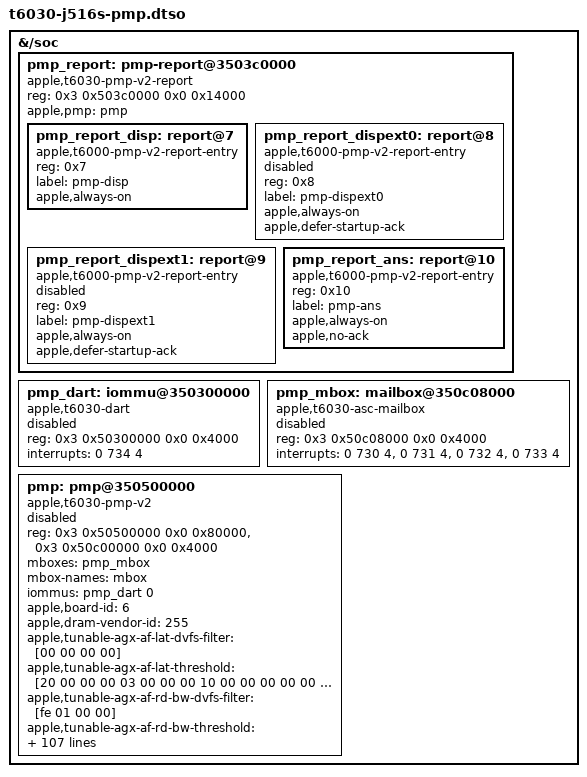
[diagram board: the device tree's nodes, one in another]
// SPDX-License-Identifier: GPL-2.0+ OR MIT
/*
 * J516S (T6030) power management processor, added by the T6030 display
 * gate when it enables the internal display.
 *
 * The PMP, its DART and its mailbox stay disabled here. The PMP report
 * driver sets the display and storage requests in the PTD while the PMP is
 * halted, and enables these nodes, which starts the PMP, only when the
 * display driver first asks for it. The PMP then keeps both powered from
 * the moment it starts.
 * The gate adds the interrupt parent of the DART and the mailbox, which
 * lives in the base tree, and points the DCP at the display report.
 *
 * Addresses, interrupts, the board and DRAM vendor ids and every
 * apple,tunable-* value are those of the J516S ADT pmp, iop-pmp-nub and
 * dart-pmp nodes. apple,tunable-uuid names the firmware image iBoot loads
 * into the PMP SRAM; the report driver refuses to start any other image.
 */

/dts-v1/;
/plugin/;

/ {
	fragment@0 {
		target-path = "/soc";

		__overlay__ {
			#address-cells = <2>;
			#size-cells = <2>;

			pmp_report: pmp-report@3503c0000 {
				compatible = "apple,t6030-pmp-v2-report";
				/* PTD read aperture and update page */
				reg = <0x3 0x503c0000 0x0 0x14000>;
				#address-cells = <1>;
				#size-cells = <0>;
				apple,pmp = <&pmp>;

				/*
				 * The gate points the DCP at this entry (apple,pmp-report)
				 * through the phandle; the overlay itself does not refer to it.
				 */
				pmp_report_disp: report@7 {
					compatible = "apple,t6000-pmp-v2-report-entry";
					reg = <0x7>;
					label = "pmp-disp";
					#power-domain-cells = <0>;
					apple,always-on;
					phandle = <0x100>;
				};

				/* Enabled only by the explicit dcpext gate, before PMP starts. */
				pmp_report_dispext0: report@8 {
					compatible = "apple,t6000-pmp-v2-report-entry";
					reg = <0x8>;
					label = "pmp-dispext0";
					#power-domain-cells = <0>;
					apple,always-on;
					/* Missing external ACK must not block the internal panel. */
					apple,defer-startup-ack;
					phandle = <0x101>;
					status = "disabled";
				};

				/*
				 * The second external display processor. Disabled: no boot
				 * loader hands that processor over yet, so nothing enables it.
				 */
				pmp_report_dispext1: report@9 {
					compatible = "apple,t6000-pmp-v2-report-entry";
					reg = <0x9>;
					label = "pmp-dispext1";
					#power-domain-cells = <0>;
					apple,always-on;
					/* Missing external ACK must not block the internal panel. */
					apple,defer-startup-ack;
					phandle = <0x102>;
					status = "disabled";
				};

				pmp_report_ans: report@10 {
					compatible = "apple,t6000-pmp-v2-report-entry";
					reg = <0x10>;
					label = "pmp-ans";
					#power-domain-cells = <0>;
					apple,always-on;
					/* The PMP does not acknowledge storage requests. */
					apple,no-ack;
				};
			};

			pmp_dart: iommu@350300000 {
				compatible = "apple,t6030-dart", "apple,t8110-dart";
				reg = <0x3 0x50300000 0x0 0x4000>;
				#iommu-cells = <1>;
				interrupts = <0 734 4>;
				status = "disabled";
			};

			pmp_mbox: mailbox@350c08000 {
				compatible = "apple,t6030-asc-mailbox", "apple,asc-mailbox-v4";
				reg = <0x3 0x50c08000 0x0 0x4000>;
				interrupts = <0 730 4>, <0 731 4>, <0 732 4>, <0 733 4>;
				interrupt-names = "send-empty", "send-not-empty",
						  "recv-empty", "recv-not-empty";
				#mbox-cells = <0>;
				status = "disabled";
			};

			pmp: pmp@350500000 {
				compatible = "apple,t6030-pmp-v2", "apple,t6000-pmp-v2";
				reg = <0x3 0x50500000 0x0 0x80000>,
				      <0x3 0x50c00000 0x0 0x4000>;
				reg-names = "pmp", "asc";
				mboxes = <&pmp_mbox>;
				mbox-names = "mbox";
				iommus = <&pmp_dart 0>;
				status = "disabled";
				apple,board-id = <6>;
				apple,dram-vendor-id = <255>;
				apple,tunable-agx-af-lat-dvfs-filter = [00 00 00 00];
				apple,tunable-agx-af-lat-threshold = [20 00 00 00 03 00 00 00 10 00 00 00 00 00 00 00 90 01 00 00 00 00 00 00 c8 00 00 00 03 00 00 00 20 00 00 00 03 00 00 00 10 00 00 00 00 00 00 00 90 01 00 00 00 00 00 00 c8 00 00 00 03 00 00 00 20 00 00 00 03 00 00 00 10 00 00 00 00 00 00 00 90 01 00 00 00 00 00 00 c8 00 00 00 03 00 00 00 20 00 00 00 03 00 00 00 10 00 00 00 00 00 00 00 90 01 00 00 00 00 00 00 c8 00 00 00 03 00 00 00 20 00 00 00 03 00 00 00 10 00 00 00 00 00 00 00 90 01 00 00 00 00 00 00 c8 00 00 00 03 00 00 00 20 00 00 00 03 00 00 00 10 00 00 00 00 00 00 00 90 01 00 00 00 00 00 00 c8 00 00 00 03 00 00 00 20 00 00 00 03 00 00 00 10 00 00 00 00 00 00 00 90 01 00 00 00 00 00 00 c8 00 00 00 03 00 00 00 20 00 00 00 03 00 00 00 10 00 00 00 00 00 00 00 90 01 00 00 00 00 00 00 c8 00 00 00 03 00 00 00 20 00 00 00 03 00 00 00 10 00 00 00 00 00 00 00 90 01 00 00 00 00 00 00 c8 00 00 00 03 00 00 00 20 00 00 00 03 00 00 00 10 00 00 00 00 00 00 00 90 01 00 00 00 00 00 00 c8 00 00 00 03 00 00 00 20 00 00 00 03 00 00 00 10 00 00 00 00 00 00 00 90 01 00 00 00 00 00 00 c8 00 00 00 03 00 00 00 20 00 00 00 03 00 00 00 10 00 00 00 00 00 00 00 90 01 00 00 00 00 00 00 c8 00 00 00 03 00 00 00 20 00 00 00 03 00 00 00 10 00 00 00 00 00 00 00 90 01 00 00 00 00 00 00 c8 00 00 00 03 00 00 00 20 00 00 00 03 00 00 00 10 00 00 00 00 00 00 00 90 01 00 00 00 00 00 00 c8 00 00 00 03 00 00 00 20 00 00 00 03 00 00 00 10 00 00 00 00 00 00 00 90 01 00 00 00 00 00 00 c8 00 00 00 03 00 00 00 20 00 00 00 03 00 00 00 10 00 00 00 00 00 00 00 90 01 00 00 00 00 00 00 c8 00 00 00 03 00 00 00 20 00 00 00 03 00 00 00 10 00 00 00 00 00 00 00 90 01 00 00 00 00 00 00 c8 00 00 00 03 00 00 00 20 00 00 00 03 00 00 00 10 00 00 00 00 00 00 00 90 01 00 00 00 00 00 00 c8 00 00 00 03 00 00 00 20 00 00 00 03 00 00 00 10 00 00 00 00 00 00 00 90 01 00 00 00 00 00 00 c8 00 00 00 03 00 00 00 20 00 00 00 03 00 00 00 10 00 00 00 00 00 00 00 90 01 00 00 00 00 00 00 c8 00 00 00 03 00 00 00 20 00 00 00 03 00 00 00 10 00 00 00 00 00 00 00 90 01 00 00 00 00 00 00 c8 00 00 00 03 00 00 00 20 00 00 00 03 00 00 00 10 00 00 00 00 00 00 00 90 01 00 00 00 00 00 00 c8 00 00 00 03 00 00 00 20 00 00 00 03 00 00 00 10 00 00 00 00 00 00 00 90 01 00 00 00 00 00 00 c8 00 00 00 03 00 00 00 20 00 00 00 03 00 00 00 10 00 00 00 00 00 00 00 90 01 00 00 00 00 00 00 c8 00 00 00 03 00 00 00 20 00 00 00 03 00 00 00 10 00 00 00 00 00 00 00 90 01 00 00 00 00 00 00 c8 00 00 00 03 00 00 00 20 00 00 00 03 00 00 00 10 00 00 00 00 00 00 00 90 01 00 00 00 00 00 00 c8 00 00 00 03 00 00 00 20 00 00 00 03 00 00 00 10 00 00 00 00 00 00 00 90 01 00 00 00 00 00 00 c8 00 00 00 03 00 00 00];
				apple,tunable-agx-af-rd-bw-dvfs-filter = [fe 01 00 00];
				apple,tunable-agx-af-rd-bw-threshold = [00 00 00 00 00 00 00 00 00 00 00 00 00 00 00 00 00 00 00 00 00 00 00 00 00 00 00 00 06 00 00 00 00 00 00 00 00 00 00 00 00 00 00 00 06 00 00 00 00 00 37 00 00 00 00 00 00 00 00 00 00 00 00 00 00 00 57 00 00 00 00 00 00 00 36 00 06 00 00 00 00 00 00 00 00 00 00 00 00 00 56 00 06 00 00 00 00 00 1e 00 00 00 00 00 00 00 00 00 00 00 00 00 00 00 57 00 00 00 00 00 00 00 1d 00 06 00 00 00 00 00 00 00 00 00 00 00 00 00 56 00 06 00 00 00 00 00 16 00 00 00 00 00 00 00 00 00 00 00 00 00 00 00 57 00 00 00 00 00 00 00 15 00 06 00 00 00 00 00 00 00 00 00 00 00 00 00 56 00 06 00 00 00 00 00 0a 00 00 00 00 00 00 00 00 00 00 00 00 00 00 00 57 00 00 00 00 00 00 00 09 00 06 00 00 00 00 00 00 00 00 00 00 00 00 00 56 00 06 00 00 00 00 00 01 00 00 00 00 00 00 00 00 00 00 00 00 00 00 00 57 00 00 00 00 00 00 00 00 00 06 00 00 00 00 00 00 00 00 00 00 00 00 00 56 00 06 00 00 00 00 00 01 00 00 00 00 00 00 00 00 00 00 00 00 00 00 00 14 00 00 00 00 00 00 00 00 00 06 00 00 00 00 00 00 00 00 00 00 00 00 00 13 00 06 00 00 00 00 00 01 00 00 00 00 00 00 00 00 00 00 00 00 00 00 00 01 00 00 00 00 00 00 00 00 00 06 00 00 00 00 00 00 00 00 00 00 00 00 00 00 00 06 00 00 00 00 00 01 00 00 00 00 00 00 00 00 00 00 00 00 00 00 00 01 00 00 00 00 00 00 00 00 00 06 00 00 00 00 00 00 00 00 00 00 00 00 00 00 00 06 00 00 00];
				apple,tunable-agx-af-wr-bw-dvfs-filter = [fe 01 00 00];
				apple,tunable-agx-af-wr-bw-threshold = [00 00 00 00 00 00 00 00 00 00 00 00 00 00 00 00 00 00 00 00 00 00 00 00 00 00 00 00 06 00 00 00 00 00 00 00 00 00 00 00 00 00 00 00 06 00 00 00 00 00 37 00 00 00 00 00 00 00 00 00 00 00 00 00 00 00 57 00 00 00 00 00 00 00 36 00 06 00 00 00 00 00 00 00 00 00 00 00 00 00 56 00 06 00 00 00 00 00 1e 00 00 00 00 00 00 00 00 00 00 00 00 00 00 00 57 00 00 00 00 00 00 00 1d 00 06 00 00 00 00 00 00 00 00 00 00 00 00 00 56 00 06 00 00 00 00 00 16 00 00 00 00 00 00 00 00 00 00 00 00 00 00 00 57 00 00 00 00 00 00 00 15 00 06 00 00 00 00 00 00 00 00 00 00 00 00 00 56 00 06 00 00 00 00 00 0a 00 00 00 00 00 00 00 00 00 00 00 00 00 00 00 57 00 00 00 00 00 00 00 09 00 06 00 00 00 00 00 00 00 00 00 00 00 00 00 56 00 06 00 00 00 00 00 01 00 00 00 00 00 00 00 00 00 00 00 00 00 00 00 57 00 00 00 00 00 00 00 00 00 06 00 00 00 00 00 00 00 00 00 00 00 00 00 56 00 06 00 00 00 00 00 01 00 00 00 00 00 00 00 00 00 00 00 00 00 00 00 14 00 00 00 00 00 00 00 00 00 06 00 00 00 00 00 00 00 00 00 00 00 00 00 13 00 06 00 00 00 00 00 01 00 00 00 00 00 00 00 00 00 00 00 00 00 00 00 01 00 00 00 00 00 00 00 00 00 06 00 00 00 00 00 00 00 00 00 00 00 00 00 00 00 06 00 00 00 00 00 01 00 00 00 00 00 00 00 00 00 00 00 00 00 00 00 01 00 00 00 00 00 00 00 00 00 06 00 00 00 00 00 00 00 00 00 00 00 00 00 00 00 06 00 00 00];
				apple,tunable-agx-dcs-bw-dvfs-filter = [fe 01 00 00];
				apple,tunable-agx-dcs-bw-threshold = [00 00 00 00 00 00 00 00 00 00 00 00 00 00 00 00 00 00 00 00 00 00 00 00 00 00 00 00 06 00 00 00 00 00 00 00 00 00 00 00 00 00 00 00 06 00 00 00 00 00 00 00 00 00 00 00 00 00 00 00 06 00 00 00 00 00 00 00 00 00 00 00 00 00 00 00 06 00 00 00 00 00 10 00 00 00 00 00 00 00 00 00 00 00 00 00 00 00 3c 00 00 00 00 00 00 00 0f 00 06 00 00 00 00 00 4c 00 00 00 00 00 00 00 3b 00 06 00 00 00 00 00 66 00 00 00 00 00 00 00 4b 00 06 00 00 00 00 00 00 00 00 00 00 00 00 00 65 00 06 00 00 00 00 00 0a 00 00 00 00 00 00 00 00 00 00 00 00 00 00 00 3c 00 00 00 00 00 00 00 09 00 06 00 00 00 00 00 4c 00 00 00 00 00 00 00 3b 00 06 00 00 00 00 00 66 00 00 00 00 00 00 00 4b 00 06 00 00 00 00 00 00 00 00 00 00 00 00 00 65 00 06 00 00 00 00 00 04 00 00 00 00 00 00 00 00 00 00 00 00 00 00 00 2c 00 00 00 00 00 00 00 03 00 06 00 00 00 00 00 4c 00 00 00 00 00 00 00 2b 00 06 00 00 00 00 00 57 00 00 00 00 00 00 00 4b 00 06 00 00 00 00 00 00 00 00 00 00 00 00 00 56 00 06 00 00 00 00 00 01 00 00 00 00 00 00 00 00 00 00 00 00 00 00 00 1a 00 00 00 00 00 00 00 00 00 06 00 00 00 00 00 26 00 00 00 00 00 00 00 19 00 06 00 00 00 00 00 57 00 00 00 00 00 00 00 25 00 06 00 00 00 00 00 00 00 00 00 00 00 00 00 56 00 06 00 00 00 00 00 01 00 00 00 00 00 00 00 00 00 00 00 00 00 00 00 01 00 00 00 00 00 00 00 00 00 06 00 00 00 00 00 0c 00 00 00 00 00 00 00 00 00 06 00 00 00 00 00 33 00 00 00 00 00 00 00 0b 00 06 00 00 00 00 00 00 00 00 00 00 00 00 00 32 00 06 00 00 00 00 00 01 00 00 00 00 00 00 00 00 00 00 00 00 00 00 00 01 00 00 00 00 00 00 00 00 00 06 00 00 00 00 00 01 00 00 00 00 00 00 00 00 00 06 00 00 00 00 00 20 00 00 00 00 00 00 00 00 00 06 00 00 00 00 00 00 00 00 00 00 00 00 00 1f 00 06 00 00 00 00 00 01 00 00 00 00 00 00 00 00 00 00 00 00 00 00 00 01 00 00 00 00 00 00 00 00 00 06 00 00 00 00 00 01 00 00 00 00 00 00 00 00 00 06 00 00 00 00 00 01 00 00 00 00 00 00 00 00 00 06 00 00 00 00 00 00 00 00 00 00 00 00 00 00 00 06 00 00 00 00 00 01 00 00 00 00 00 00 00 00 00 00 00 00 00 00 00 01 00 00 00 00 00 00 00 00 00 06 00 00 00 00 00 01 00 00 00 00 00 00 00 00 00 06 00 00 00 00 00 01 00 00 00 00 00 00 00 00 00 06 00 00 00 00 00 00 00 00 00 00 00 00 00 00 00 06 00 00 00];
				apple,tunable-agx-dcs-lat-dvfs-filter = [00 00 00 00];
				apple,tunable-agx-dcs-lat-threshold = [20 00 00 00 03 00 00 00 10 00 00 00 00 00 00 00 90 01 00 00 00 00 00 00 c8 00 00 00 03 00 00 00 20 00 00 00 03 00 00 00 10 00 00 00 00 00 00 00 90 01 00 00 00 00 00 00 c8 00 00 00 03 00 00 00 20 00 00 00 03 00 00 00 10 00 00 00 00 00 00 00 90 01 00 00 00 00 00 00 c8 00 00 00 03 00 00 00 20 00 00 00 03 00 00 00 10 00 00 00 00 00 00 00 90 01 00 00 00 00 00 00 c8 00 00 00 03 00 00 00 20 00 00 00 03 00 00 00 10 00 00 00 00 00 00 00 90 01 00 00 00 00 00 00 c8 00 00 00 03 00 00 00 20 00 00 00 03 00 00 00 10 00 00 00 00 00 00 00 90 01 00 00 00 00 00 00 c8 00 00 00 03 00 00 00 20 00 00 00 03 00 00 00 10 00 00 00 00 00 00 00 90 01 00 00 00 00 00 00 c8 00 00 00 03 00 00 00 20 00 00 00 03 00 00 00 10 00 00 00 00 00 00 00 90 01 00 00 00 00 00 00 c8 00 00 00 03 00 00 00 20 00 00 00 03 00 00 00 10 00 00 00 00 00 00 00 90 01 00 00 00 00 00 00 c8 00 00 00 03 00 00 00 20 00 00 00 03 00 00 00 10 00 00 00 00 00 00 00 90 01 00 00 00 00 00 00 c8 00 00 00 03 00 00 00 20 00 00 00 03 00 00 00 10 00 00 00 00 00 00 00 90 01 00 00 00 00 00 00 c8 00 00 00 03 00 00 00 20 00 00 00 03 00 00 00 10 00 00 00 00 00 00 00 90 01 00 00 00 00 00 00 c8 00 00 00 03 00 00 00 20 00 00 00 03 00 00 00 10 00 00 00 00 00 00 00 90 01 00 00 00 00 00 00 c8 00 00 00 03 00 00 00 20 00 00 00 03 00 00 00 10 00 00 00 00 00 00 00 90 01 00 00 00 00 00 00 c8 00 00 00 03 00 00 00 20 00 00 00 03 00 00 00 10 00 00 00 00 00 00 00 90 01 00 00 00 00 00 00 c8 00 00 00 03 00 00 00 20 00 00 00 03 00 00 00 10 00 00 00 00 00 00 00 90 01 00 00 00 00 00 00 c8 00 00 00 03 00 00 00 20 00 00 00 03 00 00 00 10 00 00 00 00 00 00 00 90 01 00 00 00 00 00 00 c8 00 00 00 03 00 00 00 20 00 00 00 03 00 00 00 10 00 00 00 00 00 00 00 90 01 00 00 00 00 00 00 c8 00 00 00 03 00 00 00 20 00 00 00 03 00 00 00 10 00 00 00 00 00 00 00 90 01 00 00 00 00 00 00 c8 00 00 00 03 00 00 00 20 00 00 00 03 00 00 00 10 00 00 00 00 00 00 00 90 01 00 00 00 00 00 00 c8 00 00 00 03 00 00 00 20 00 00 00 03 00 00 00 10 00 00 00 00 00 00 00 90 01 00 00 00 00 00 00 c8 00 00 00 03 00 00 00 20 00 00 00 03 00 00 00 10 00 00 00 00 00 00 00 90 01 00 00 00 00 00 00 c8 00 00 00 03 00 00 00 20 00 00 00 03 00 00 00 10 00 00 00 00 00 00 00 90 01 00 00 00 00 00 00 c8 00 00 00 03 00 00 00 20 00 00 00 03 00 00 00 10 00 00 00 00 00 00 00 90 01 00 00 00 00 00 00 c8 00 00 00 03 00 00 00 20 00 00 00 03 00 00 00 10 00 00 00 00 00 00 00 90 01 00 00 00 00 00 00 c8 00 00 00 03 00 00 00 20 00 00 00 03 00 00 00 10 00 00 00 00 00 00 00 90 01 00 00 00 00 00 00 c8 00 00 00 03 00 00 00 20 00 00 00 03 00 00 00 10 00 00 00 00 00 00 00 90 01 00 00 00 00 00 00 c8 00 00 00 03 00 00 00 20 00 00 00 03 00 00 00 10 00 00 00 00 00 00 00 90 01 00 00 00 00 00 00 c8 00 00 00 03 00 00 00 20 00 00 00 03 00 00 00 10 00 00 00 00 00 00 00 90 01 00 00 00 00 00 00 c8 00 00 00 03 00 00 00 20 00 00 00 03 00 00 00 10 00 00 00 00 00 00 00 90 01 00 00 00 00 00 00 c8 00 00 00 03 00 00 00 20 00 00 00 03 00 00 00 10 00 00 00 00 00 00 00 90 01 00 00 00 00 00 00 c8 00 00 00 03 00 00 00 20 00 00 00 03 00 00 00 10 00 00 00 00 00 00 00 90 01 00 00 00 00 00 00 c8 00 00 00 03 00 00 00 20 00 00 00 03 00 00 00 10 00 00 00 00 00 00 00 90 01 00 00 00 00 00 00 c8 00 00 00 03 00 00 00 20 00 00 00 03 00 00 00 10 00 00 00 00 00 00 00 90 01 00 00 00 00 00 00 c8 00 00 00 03 00 00 00 20 00 00 00 03 00 00 00 10 00 00 00 00 00 00 00 90 01 00 00 00 00 00 00 c8 00 00 00 03 00 00 00 20 00 00 00 03 00 00 00 10 00 00 00 00 00 00 00 90 01 00 00 00 00 00 00 c8 00 00 00 03 00 00 00 20 00 00 00 03 00 00 00 10 00 00 00 00 00 00 00 90 01 00 00 00 00 00 00 c8 00 00 00 03 00 00 00 20 00 00 00 03 00 00 00 10 00 00 00 00 00 00 00 90 01 00 00 00 00 00 00 c8 00 00 00 03 00 00 00 20 00 00 00 03 00 00 00 10 00 00 00 00 00 00 00 90 01 00 00 00 00 00 00 c8 00 00 00 03 00 00 00 20 00 00 00 03 00 00 00 10 00 00 00 00 00 00 00 90 01 00 00 00 00 00 00 c8 00 00 00 03 00 00 00 20 00 00 00 03 00 00 00 10 00 00 00 00 00 00 00 90 01 00 00 00 00 00 00 c8 00 00 00 03 00 00 00 20 00 00 00 03 00 00 00 10 00 00 00 00 00 00 00 90 01 00 00 00 00 00 00 c8 00 00 00 03 00 00 00 20 00 00 00 03 00 00 00 10 00 00 00 00 00 00 00 90 01 00 00 00 00 00 00 c8 00 00 00 03 00 00 00 20 00 00 00 03 00 00 00 10 00 00 00 00 00 00 00 90 01 00 00 00 00 00 00 c8 00 00 00 03 00 00 00 20 00 00 00 03 00 00 00 10 00 00 00 00 00 00 00 90 01 00 00 00 00 00 00 c8 00 00 00 03 00 00 00];
				apple,tunable-agx-dvfs-state-voltages = [7d 00 00 00 8f 02 00 00 b7 02 00 00 cb 02 00 00 ee 02 00 00 ee 02 00 00 2a 03 00 00 2a 03 00 00 6b 03 00 00 6b 03 00 00 9d 03 00 00 9d 03 00 00 bb 03 00 00 bb 03 00 00 7d 00 00 00 7d 00 00 00];
				apple,tunable-ane-fast-af-bw-dvfs-filter = [e0 ff ff 0f];
				apple,tunable-ane-fast-af-bw-threshold = [00 00 05 00 00 00 00 00 00 00 00 00 00 00 00 00 00 00 0e 00 00 00 00 00 00 00 04 00 06 00 00 00 00 00 00 00 00 00 00 00 00 00 0d 00 06 00 00 00];
				apple,tunable-ane-fast-bw-dvfs-filter = [e0 ff ff 0f];
				apple,tunable-ane-fast-bw-threshold = [00 00 05 00 00 00 00 00 00 00 00 00 00 00 00 00 00 00 0e 00 00 00 00 00 00 00 04 00 06 00 00 00 00 00 00 00 00 00 00 00 00 00 0d 00 06 00 00 00];
				apple,tunable-ane-fast-dcs-bw-dvfs-filter = [00 fe ff 0f];
				apple,tunable-ane-fast-dcs-bw-threshold = [00 00 07 00 00 00 00 00 00 00 00 00 00 00 00 00 00 00 0f 00 00 00 00 00 00 00 06 00 06 00 00 00 00 00 2d 00 00 00 00 00 00 00 0e 00 06 00 00 00 00 00 4b 00 00 00 00 00 00 00 2c 00 06 00 00 00 00 00 00 00 00 00 00 00 00 00 4a 00 06 00 00 00];
				apple,tunable-ane-slow-af-bw-dvfs-filter = [1c 00 00 00];
				apple,tunable-ane-slow-af-bw-threshold = [47 a1 19 00 00 00 00 00 00 00 00 00 00 00 00 00 14 2e 22 00 00 00 00 00 47 a1 18 00 03 00 00 00 00 00 00 00 00 00 00 00 14 2e 21 00 03 00 00 00];
				apple,tunable-ane-slow-bw-dvfs-filter = [1f 00 00 00];
				apple,tunable-ane-slow-bw-threshold = [47 a1 19 00 00 00 00 00 00 00 00 00 00 00 00 00 14 2e 22 00 00 00 00 00 47 a1 18 00 03 00 00 00 00 00 00 00 00 00 00 00 14 2e 21 00 03 00 00 00];
				apple,tunable-ane-slow-dcs-bw-dvfs-filter = [e0 01 00 00];
				apple,tunable-ane-slow-dcs-bw-threshold = [00 00 0f 00 00 00 00 00 00 00 00 00 00 00 00 00 00 00 2a 00 00 00 00 00 00 00 0e 00 06 00 00 00 00 00 52 00 00 00 00 00 00 00 29 00 06 00 00 00 00 00 69 00 00 00 00 00 00 00 51 00 06 00 00 00 00 00 00 00 00 00 00 00 00 00 68 00 06 00 00 00];
				apple,tunable-bwr-catch-up-factor = [00 00 01 00];
				apple,tunable-controller = [01 00 00 00 1f 00 00 00 43 00 00 00 44 49 45 2d 54 45 4d 50 00 00 00 00 00 00 00 00 00 00 00 00 00 00 00 00 00 00 00 00 00 00 00 00 02 00 00 00 00 00 00 00 00 00 00 00 44 43 53 2d 42 57 00 00 00 00 00 00 00 00 00 00 00 00 00 00 00 00 00 00 00 00 00 00 00 00 00 00 03 00 00 00 00 00 00 00 00 00 00 00 41 47 58 2d 41 46 2d 52 44 2d 42 57 00 00 00 00 00 00 00 00 00 00 00 00 00 00 00 00 00 00 00 00 05 00 00 00 00 00 00 00 00 00 00 00 41 47 58 2d 41 46 2d 57 52 2d 42 57 00 00 00 00 00 00 00 00 00 00 00 00 00 00 00 00 00 00 00 00 07 00 00 00 00 00 00 00 00 00 00 00 41 47 58 2d 44 43 53 2d 42 57 00 00 00 00 00 00 00 00 00 00 00 00 00 00 00 00 00 00 00 00 00 00 09 00 00 00 00 00 00 00 00 00 00 00 44 43 53 2d 42 57 52 00 00 00 00 00 00 00 00 00 00 00 00 00 00 00 00 00 00 00 00 00 00 00 00 00 0a 00 00 00 00 00 00 00 00 00 00 00 44 43 53 2d 52 44 2d 42 57 52 00 00 00 00 00 00 00 00 00 00 00 00 00 00 00 00 00 00 00 00 00 00 0b 00 00 00 00 00 00 00 00 00 00 00 44 43 53 2d 57 52 2d 42 57 52 00 00 00 00 00 00 00 00 00 00 00 00 00 00 00 00 00 00 00 00 00 00 0c 00 00 00 00 00 00 00 00 00 00 00 53 4f 43 30 2d 52 44 2d 42 57 52 00 00 00 00 00 00 00 00 00 00 00 00 00 00 00 00 00 00 00 00 00 0d 00 00 00 00 00 00 00 00 00 00 00 53 4f 43 30 2d 57 52 2d 42 57 52 00 00 00 00 00 00 00 00 00 00 00 00 00 00 00 00 00 00 00 00 00 0e 00 00 00 00 00 00 00 00 00 00 00 53 4f 43 31 2d 52 44 2d 42 57 52 00 00 00 00 00 00 00 00 00 00 00 00 00 00 00 00 00 00 00 00 00 0f 00 00 00 00 00 00 00 00 00 00 00 53 4f 43 31 2d 57 52 2d 42 57 52 00 00 00 00 00 00 00 00 00 00 00 00 00 00 00 00 00 00 00 00 00 10 00 00 00 00 00 00 00 00 00 00 00 41 4e 45 2d 53 4c 4f 57 2d 44 43 53 2d 42 57 00 00 00 00 00 00 00 00 00 00 00 00 00 00 00 00 00 11 00 00 00 00 00 00 00 00 00 00 00 41 4e 45 2d 46 41 53 54 2d 44 43 53 2d 42 57 00 00 00 00 00 00 00 00 00 00 00 00 00 00 00 00 00 12 00 00 00 00 00 00 00 00 00 00 00 41 4e 45 2d 53 4c 4f 57 2d 41 46 2d 42 57 00 00 00 00 00 00 00 00 00 00 00 00 00 00 00 00 00 00 13 00 00 00 00 00 00 00 00 00 00 00 41 4e 45 2d 46 41 53 54 2d 41 46 2d 42 57 00 00 00 00 00 00 00 00 00 00 00 00 00 00 00 00 00 00 14 00 00 00 00 00 00 00 00 00 00 00 41 4e 45 2d 53 4c 4f 57 2d 42 57 00 00 00 00 00 00 00 00 00 00 00 00 00 00 00 00 00 00 00 00 00 15 00 00 00 00 00 00 00 00 00 00 00 41 4e 45 2d 46 41 53 54 2d 42 57 00 00 00 00 00 00 00 00 00 00 00 00 00 00 00 00 00 00 00 00 00 16 00 00 00 0e 00 00 00 1e 00 00 00 4d 45 4d 2d 43 41 43 48 45 00 00 00 00 00 00 00 00 00 00 00 00 00 00 00 00 00 00 00 00 00 00 00 17 00 00 00 00 00 00 00 00 00 00 00 41 47 58 2d 41 46 2d 4c 41 54 00 00 00 00 00 00 00 00 00 00 00 00 00 00 00 00 00 00 00 00 00 00 18 00 00 00 00 00 00 00 00 00 00 00 41 47 58 2d 44 43 53 2d 4c 41 54 00 00 00 00 00 00 00 00 00 00 00 00 00 00 00 00 00 00 00 00 00 19 00 00 00 00 00 00 00 00 00 00 00 49 4f 41 30 2d 41 46 4e 43 2d 42 57 00 00 00 00 00 00 00 00 00 00 00 00 00 00 00 00 00 00 00 00 1a 00 00 00 00 00 00 00 00 00 00 00 49 4f 41 31 2d 41 46 4e 43 2d 42 57 00 00 00 00 00 00 00 00 00 00 00 00 00 00 00 00 00 00 00 00 1b 00 00 00 00 00 00 00 00 00 00 00 49 4f 41 32 2d 41 46 4e 43 2d 42 57 00 00 00 00 00 00 00 00 00 00 00 00 00 00 00 00 00 00 00 00 1c 00 00 00 00 00 00 00 00 00 00 00 49 4f 41 33 2d 41 46 4e 43 2d 42 57 00 00 00 00 00 00 00 00 00 00 00 00 00 00 00 00 00 00 00 00];
				apple,tunable-dcs-bw-threshold = [7a d4 1d 00 00 00 00 00 00 00 00 00 00 00 00 00 00 c0 3b 00 00 00 00 00 7a d4 1c 00 03 00 00 00 3d 0a 57 00 00 00 00 00 00 c0 3a 00 03 00 00 00 1e 85 6f 00 00 00 00 00 3d 0a 56 00 03 00 00 00 00 00 00 00 00 00 00 00 1e 85 6e 00 03 00 00 00];
				apple,tunable-dcs-bwr-threshold = [00 80 11 00 99 19 23 00 33 33 33 00 99 99 41 00 cc cc 4c 00];
				apple,tunable-dcs-rd-bwr-threshold = [00 80 11 00 99 19 23 00 33 33 33 00 99 99 41 00 cc cc 4c 00];
				apple,tunable-dcs-wr-bwr-threshold = [00 80 0a 00 99 19 15 00 33 b3 1e 00 66 66 27 00 99 19 2e 00];
				apple,tunable-dvfs-disp-min-state = [00 00 00 00];
				apple,tunable-dvfs-domain = [01 00 00 00 05 00 00 00 00 00 00 00 44 43 53 00 00 00 00 00 00 00 00 00 00 00 00 00 02 00 00 00 03 00 00 00 00 00 00 00 53 4f 43 00 00 00 00 00 00 00 00 00 00 00 00 00 03 00 00 00 03 00 00 00 00 00 00 00 44 49 53 50 5f 49 4e 54 00 00 00 00 00 00 00 00 04 00 00 00 03 00 00 00 00 00 00 00 46 41 42 00 00 00 00 00 00 00 00 00 00 00 00 00 05 00 00 00 04 00 00 00 00 00 00 00 44 49 53 50 5f 45 58 54 00 00 00 00 00 00 00 00];
				apple,tunable-fast-die-ctrl-ce-map = [01 00 00 00 00 00 00 00 00 00 00 00 01 00 00 00 00 00 00 00 00 00 00 00 00 00 00 00 45 41 43 43 00 00 00 00 00 00 00 00 00 00 00 00 02 00 00 00 00 00 00 00 01 00 00 00 02 00 00 00 03 00 00 00 00 00 00 00 00 00 00 00 50 41 43 43 5f 41 4e 45 00 00 00 00 00 00 00 00];
				apple,tunable-fast-die-ctrl-loop = [01 00 00 00 00 00 00 00 00 00 00 00 ae 05 00 00 cc cc 07 00 00 00 6e 00 00 00 01 00 00 00 00 00 00 00 01 00 00 00 00 00 00 00 00 00 00 00 01 00 16 00 00 00 02 00 00 00 03 00 00 00 00 00 00 00 00 00 00 00 00 00 00 00 00 00 00 00 00 00 00 00 00 00 00 00 00 00 00 00 00 00 00 00 00 00 00 00 00 00 00 00 00 00 00 00 00 00 00 00 00 00 00 00 00 00 00 00 45 41 43 43 00 00 00 00 00 00 00 00 00 00 00 00 02 00 00 00 00 00 00 00 01 00 00 00 ae 05 00 00 cc cc 07 00 00 00 6e 00 00 00 01 00 00 00 00 00 00 00 01 00 00 00 00 00 00 00 00 00 00 00 01 00 16 00 00 00 04 00 00 00 05 00 00 00 06 00 00 00 00 00 00 00 00 00 00 00 00 00 00 00 00 00 00 00 00 00 00 00 00 00 00 00 00 00 00 00 00 00 00 00 00 00 00 00 00 00 00 00 00 00 00 00 00 00 00 00 00 00 00 00 50 41 43 43 00 00 00 00 00 00 00 00 00 00 00 00 03 00 00 00 00 00 00 00 02 00 00 00 ae 05 00 00 cc cc 07 00 00 00 6e 00 00 00 01 00 00 00 00 00 00 00 01 00 00 00 00 00 00 00 00 00 00 00 01 00 16 00 00 00 01 00 00 00 00 00 00 00 00 00 00 00 00 00 00 00 00 00 00 00 00 00 00 00 00 00 00 00 00 00 00 00 00 00 00 00 00 00 00 00 00 00 00 00 00 00 00 00 00 00 00 00 00 00 00 00 00 00 00 00 00 00 00 00 41 4e 45 30 00 00 00 00 00 00 00 00 00 00 00 00];
				apple,tunable-fast-die-ctrl-ts = [00 00 05 00];
				apple,tunable-fast-die-ctrl-ts-avg-temp = [00 00 64 00];
				apple,tunable-ioa0-afnc-bw-threshold = [cc 0c 1d 00 00 00 00 00 00 00 00 00 00 00 00 00 e1 ba 26 00 00 00 00 00 cc 0c 1c 00 03 00 00 00 00 00 00 00 00 00 00 00 e1 ba 25 00 03 00 00 00];
				apple,tunable-ioa1-afnc-bw-threshold = [cc 0c 1d 00 00 00 00 00 00 00 00 00 00 00 00 00 e1 ba 26 00 00 00 00 00 cc 0c 1c 00 03 00 00 00 00 00 00 00 00 00 00 00 e1 ba 25 00 03 00 00 00];
				apple,tunable-ioa2-afnc-bw-threshold = [cc 0c 1d 00 00 00 00 00 00 00 00 00 00 00 00 00 e1 ba 26 00 00 00 00 00 cc 0c 1c 00 03 00 00 00 00 00 00 00 00 00 00 00 e1 ba 25 00 03 00 00 00];
				apple,tunable-ioa3-afnc-bw-threshold = [cc 0c 1d 00 00 00 00 00 00 00 00 00 00 00 00 00 e1 ba 26 00 00 00 00 00 cc 0c 1c 00 03 00 00 00 00 00 00 00 00 00 00 00 e1 ba 25 00 03 00 00 00];
				apple,tunable-mc_cmd_ack_ptd_count = [01 00 00 00];
				apple,tunable-mc_cmd_ptd_count = [02 00 00 00];
				apple,tunable-mc_quota_req_ptd_count = [08 00 00 00];
				apple,tunable-mc_quota_rsp_ptd_count = [08 00 00 00];
				apple,tunable-mcache-stream = [1e 00 00 00 03 00 00 00 01 00 00 00 0b 00 00 00 0e 00 00 00 0e 00 00 00 02 00 00 00 00 00 00 00 00 00 00 00 04 00 00 00 01 00 00 00 05 00 00 00 01 00 00 00 01 00 00 00 02 00 00 00 14 00 00 00 14 00 00 00 02 00 00 00 00 00 00 00 00 00 00 00 04 00 00 00 01 00 00 00 06 00 00 00 02 00 00 00 01 00 00 00 03 00 00 00 12 00 00 00 12 00 00 00 02 00 00 00 00 00 00 00 00 00 00 00 04 00 00 00 00 00 00 00 0b 00 00 00 05 00 00 00 01 00 00 00 05 00 00 00 21 00 00 00 21 00 00 00 02 00 00 00 00 00 00 00 00 00 00 00 04 00 00 00 01 00 00 00 0e 00 00 00 04 00 00 00 01 00 00 00 10 00 00 00 15 00 00 00 15 00 00 00 02 00 00 00 00 00 00 00 00 00 00 00 04 00 00 00 00 00 00 00 11 00 00 00 04 00 00 00 01 00 00 00 11 00 00 00 16 00 00 00 16 00 00 00 02 00 00 00 00 00 00 00 00 00 00 00 04 00 00 00 01 00 00 00 13 00 00 00 04 00 00 00 01 00 00 00 12 00 00 00 17 00 00 00 17 00 00 00 02 00 00 00 00 00 00 00 00 00 00 00 04 00 00 00 01 00 00 00 24 00 00 00 04 00 00 00 01 00 00 00 12 00 00 00 18 00 00 00 18 00 00 00 02 00 00 00 00 00 00 00 00 00 00 00 04 00 00 00 01 00 00 00 1b 00 00 00 04 00 00 00 01 00 00 00 11 00 00 00 1e 00 00 00 1e 00 00 00 02 00 00 00 00 00 00 00 00 00 00 00 04 00 00 00 01 00 00 00 1c 00 00 00 04 00 00 00 01 00 00 00 12 00 00 00 1f 00 00 00 1f 00 00 00 02 00 00 00 00 00 00 00 00 00 00 00 04 00 00 00 01 00 00 00 10 00 00 00 04 00 00 00 01 00 00 00 18 00 00 00 40 00 00 00 bf 00 00 00 02 00 00 00 00 00 00 00 00 00 00 00 04 00 00 00 01 00 00 00 04 00 00 00 00 00 00 00 01 00 00 00 06 00 00 00 0d 00 00 00 0d 00 00 00 02 00 00 00 00 00 00 00 00 00 00 00 05 00 00 00 01 00 00 00 02 00 00 00 00 00 00 00 01 00 00 00 04 00 00 00 13 00 00 00 13 00 00 00 02 00 00 00 00 00 00 00 00 00 00 00 04 00 00 00 01 00 00 00 01 00 00 00 00 00 00 00 01 00 00 00 0a 00 00 00 0a 00 00 00 0c 00 00 00 02 00 00 00 00 00 00 00 00 00 00 00 04 00 00 00 01 00 00 00 1f 00 00 00 03 00 00 00 02 00 00 00 0b 00 00 00 23 00 00 00 23 00 00 00 03 00 00 00 00 00 00 00 00 00 00 00 04 00 00 00 01 00 00 00 20 00 00 00 03 00 00 00 02 00 00 00 16 00 00 00 24 00 00 00 33 00 00 00 03 00 00 00 00 00 00 00 00 00 00 00 05 00 00 00 01 00 00 00 12 00 00 00 05 00 00 00 02 00 00 00 09 00 00 00 0f 00 00 00 0f 00 00 00 03 00 00 00 00 00 00 00 00 00 00 00 04 00 00 00 01 00 00 00 15 00 00 00 07 00 00 00 02 00 00 00 0f 00 00 00 11 00 00 00 11 00 00 00 03 00 00 00 00 00 00 00 00 00 00 00 04 00 00 00 01 00 00 00 21 00 00 00 0a 00 00 00 02 00 00 00 07 00 00 00 20 00 00 00 20 00 00 00 03 00 00 00 00 00 00 00 00 00 00 00 04 00 00 00 00 00 00 00 1d 00 00 00 09 00 00 00 02 00 00 00 13 00 00 00 34 00 00 00 38 00 00 00 03 00 00 00 00 00 00 00 00 00 00 00 04 00 00 00 01 00 00 00 23 00 00 00 00 00 00 00 03 00 00 00 0c 00 00 00 19 00 00 00 19 00 00 00 01 00 00 00 00 00 00 00 00 00 00 00 04 00 00 00 01 00 00 00 19 00 00 00 08 00 00 00 03 00 00 00 01 00 00 00 03 00 00 00 03 00 00 00 01 00 00 00 00 00 00 00 00 00 00 00 04 00 00 00 01 00 00 00 1a 00 00 00 08 00 00 00 03 00 00 00 01 00 00 00 04 00 00 00 04 00 00 00 01 00 00 00 00 00 00 00 00 00 00 00 04 00 00 00 01 00 00 00 29 00 00 00 08 00 00 00 03 00 00 00 01 00 00 00 05 00 00 00 05 00 00 00 01 00 00 00 00 00 00 00 00 00 00 00 04 00 00 00 01 00 00 00 2a 00 00 00 08 00 00 00 03 00 00 00 01 00 00 00 06 00 00 00 06 00 00 00 01 00 00 00 00 00 00 00 00 00 00 00 04 00 00 00 01 00 00 00 0d 00 00 00 0b 00 00 00 03 00 00 00 08 00 00 00 07 00 00 00 07 00 00 00 01 00 00 00 00 00 00 00 00 00 00 00 04 00 00 00 01 00 00 00 0c 00 00 00 0b 00 00 00 03 00 00 00 08 00 00 00 08 00 00 00 08 00 00 00 01 00 00 00 00 00 00 00 00 00 00 00 04 00 00 00 01 00 00 00 2c 00 00 00 03 00 00 00 03 00 00 00 00 00 00 00 39 00 00 00 39 00 00 00 01 00 00 00 00 00 00 00 00 00 00 00 04 00 00 00 00 00 00 00 2d 00 00 00 0c 00 00 00 03 00 00 00 00 00 00 00 3a 00 00 00 3a 00 00 00 01 00 00 00 00 00 00 00 00 00 00 00 04 00 00 00 00 00 00 00 2f 00 00 00 02 00 00 00 03 00 00 00 00 00 00 00 3c 00 00 00 3c 00 00 00 01 00 00 00 00 00 00 00 00 00 00 00 04 00 00 00 00 00 00 00 26 00 00 00 05 00 00 00 03 00 00 00 0d 00 00 00 1b 00 00 00 1b 00 00 00 01 00 00 00 00 00 00 00 00 00 00 00 04 00 00 00 00 00 00 00 14 00 00 00 04 00 00 00 03 00 00 00 08 00 00 00 09 00 00 00 09 00 00 00 01 00 00 00 00 00 00 00 00 00 00 00 04 00 00 00 01 00 00 00 27 00 00 00 04 00 00 00 03 00 00 00 14 00 00 00 1c 00 00 00 1c 00 00 00 01 00 00 00 00 00 00 00 00 00 00 00 04 00 00 00 00 00 00 00 28 00 00 00 00 00 00 00 03 00 00 00 17 00 00 00 1d 00 00 00 1d 00 00 00 01 00 00 00 00 00 00 00 00 00 00 00 04 00 00 00 00 00 00 00 30 00 00 00 0e 00 00 00 03 00 00 00 00 00 00 00 3b 00 00 00 3b 00 00 00 01 00 00 00 00 00 00 00 00 00 00 00 04 00 00 00 00 00 00 00 31 00 00 00 0f 00 00 00 03 00 00 00 00 00 00 00 3e 00 00 00 3e 00 00 00 01 00 00 00 00 00 00 00 00 00 00 00 04 00 00 00 00 00 00 00 35 00 00 00 09 00 00 00 03 00 00 00 00 00 00 00 3f 00 00 00 3f 00 00 00 01 00 00 00 00 00 00 00 00 00 00 00 04 00 00 00 00 00 00 00 16 00 00 00 0b 00 00 00 03 00 00 00 ff ff 00 00 00 00 00 00 00 00 00 00 01 00 00 00 00 00 00 00 00 00 00 00 04 00 00 00 00 00 00 00];
				apple,tunable-no-shutdown = [01 00 00 00];
				apple,tunable-pm-ptd-ranges = [01 00 00 00 02 00 00 00 03 00 00 00 04 00 00 00 05 00 00 00 06 00 00 00 07 00 00 00 08 00 00 00 00 00 00 00 09 00 00 00 0a 00 00 00 0b 00 00 00 0c 00 00 00 0d 00 00 00 00 00 00 00];
				apple,tunable-ptd-driver-version = [01 00 00 00];
				apple,tunable-ptd-range = [01 00 00 00 00 00 00 00 01 00 00 00 00 00 00 00 4e 55 4c 4c 00 00 00 00 00 00 00 00 00 00 00 00 02 00 00 00 01 00 00 00 01 00 00 00 00 00 00 00 50 4d 50 2d 53 54 41 54 55 53 00 00 00 00 00 00 03 00 00 00 08 00 00 00 04 00 00 00 00 00 00 00 44 56 46 53 2d 53 54 41 54 45 00 00 00 00 00 00 04 00 00 00 0c 00 00 00 04 00 00 00 00 00 00 00 50 4d 50 54 4f 4f 4c 00 00 00 00 00 00 00 00 00 05 00 00 00 10 00 00 00 10 00 00 00 00 00 00 00 50 4d 53 2d 50 4d 47 52 2d 50 4b 54 00 00 00 00 06 00 00 00 20 00 00 00 10 00 00 00 00 00 00 00 50 4d 53 2d 44 50 45 2d 50 4b 54 00 00 00 00 00 07 00 00 00 30 00 00 00 10 00 00 00 00 00 00 00 50 4d 53 2d 44 45 56 43 2d 50 4b 54 00 00 00 00 08 00 00 00 40 00 00 00 10 00 00 00 00 00 00 00 50 4d 53 2d 43 31 50 50 54 2d 50 4b 54 00 00 00 09 00 00 00 50 00 00 00 c8 00 00 00 00 00 00 00 53 4f 43 2d 44 45 56 2d 50 4b 54 00 00 00 00 00 0a 00 00 00 18 01 00 00 04 00 00 00 00 00 00 00 53 4f 43 2d 44 45 56 2d 50 53 2d 52 45 51 00 00 0b 00 00 00 1c 01 00 00 04 00 00 00 00 00 00 00 53 4f 43 2d 44 45 56 2d 50 53 2d 41 43 4b 00 00 0c 00 00 00 20 01 00 00 10 00 00 00 00 00 00 00 53 4f 43 2d 44 45 56 2d 44 56 46 53 00 00 00 00 0d 00 00 00 30 01 00 00 08 00 00 00 00 00 00 00 53 4f 43 2d 44 45 56 2d 42 57 52 00 00 00 00 00 0e 00 00 00 38 01 00 00 0a 00 00 00 00 00 00 00 4d 43 2d 44 52 56 2d 54 4f 2d 43 54 52 4c 00 00 1e 00 00 00 48 01 00 00 09 00 00 00 00 00 00 00 4d 43 2d 43 54 52 4c 2d 54 4f 2d 44 52 56 00 00 1f 00 00 00 51 01 00 00 02 00 00 00 0c 00 00 00 46 41 53 54 2d 44 49 45 2d 43 45 00 00 00 00 00 20 00 00 00 53 01 00 00 07 00 00 00 0d 00 00 00 53 4d 43 2d 54 4f 2d 50 50 4d 00 00 00 00 00 00 21 00 00 00 5a 01 00 00 01 00 00 00 00 00 00 00 50 4d 55 2d 54 4f 2d 43 4c 50 43 00 00 00 00 00 40 00 00 00 68 01 00 00 05 00 00 00 0e 00 00 00 50 50 4d 2d 54 4f 2d 53 4d 43 00 00 00 00 00 00 41 00 00 00 6d 01 00 00 05 00 00 00 0f 00 00 00 43 4c 50 43 2d 54 4f 2d 53 4d 43 00 00 00 00 00 42 00 00 00 72 01 00 00 10 00 00 00 00 00 00 00 47 46 58 2d 54 4f 2d 53 4d 43 00 00 00 00 00 00 43 00 00 00 82 01 00 00 02 00 00 00 00 00 00 00 46 41 53 54 2d 44 49 45 2d 54 4f 2d 53 4d 43 00 44 00 00 00 84 01 00 00 01 00 00 00 00 00 00 00 4d 43 2d 43 54 52 4c 2d 54 4f 2d 53 4d 43 00 00 45 00 00 00 85 01 00 00 05 00 00 00 00 00 00 00 41 4e 45 2d 54 4f 2d 53 4d 43 00 00 00 00 00 00 52 00 00 00 b8 01 00 00 01 00 00 00 00 00 00 00 4c 54 53 2d 54 4f 2d 47 46 58 00 00 00 00 00 00 53 00 00 00 b9 01 00 00 01 00 00 00 0b 00 00 00 50 4d 50 2d 54 4f 2d 47 46 58 00 00 00 00 00 00 54 00 00 00 ba 01 00 00 01 00 00 00 00 00 00 00 50 4d 55 2d 54 4f 2d 47 46 58 00 00 00 00 00 00];
				apple,tunable-soc-device = [01 00 00 00 45 4e 4f 4e 01 00 00 00 00 00 00 00 00 00 00 00 00 00 00 00 01 00 00 00 00 00 00 00 00 00 00 00 00 00 00 00 00 00 00 00 00 00 00 00 00 00 00 00 00 00 00 00 00 00 00 00 00 00 00 00 00 00 00 00 00 00 00 00 00 00 00 00 00 00 00 00 00 00 00 00 00 00 00 00 00 00 00 00 00 00 00 00 00 00 00 00 00 00 00 00 00 00 00 00 00 00 00 00 00 00 00 00 44 43 53 00 00 00 00 00 02 00 00 00 45 4e 4f 4e 01 00 00 00 10 00 00 00 00 00 00 00 00 00 00 00 02 00 00 00 00 00 00 00 00 00 00 00 00 00 00 00 00 00 00 00 00 00 00 00 00 00 00 00 00 00 00 00 00 00 00 00 00 00 00 00 00 00 00 00 00 00 00 00 00 00 00 00 00 00 00 00 00 00 00 00 00 00 00 00 00 00 00 00 00 00 00 00 00 00 00 00 00 00 00 00 00 00 00 00 00 00 00 00 00 00 00 00 41 4d 43 43 00 00 00 00 03 00 00 00 45 4e 4f 4e 03 00 00 00 01 00 00 00 00 00 00 00 00 00 00 00 00 00 00 00 04 00 00 00 00 00 00 00 00 00 00 00 00 00 00 00 02 00 00 00 00 00 00 00 00 00 00 00 00 00 00 00 00 00 00 00 00 00 00 00 00 00 00 00 00 00 00 00 00 00 00 00 00 00 00 00 00 00 00 00 00 00 00 00 00 00 00 00 00 00 00 00 00 00 00 00 00 00 00 00 00 00 00 00 00 00 00 00 45 41 43 43 30 00 00 00 04 00 00 00 45 4e 4f 4e 03 00 00 00 02 00 00 00 00 00 00 00 00 00 00 00 00 00 00 00 04 00 00 00 00 00 00 00 00 00 00 00 00 00 00 00 02 00 00 00 00 00 00 00 00 00 00 00 00 00 00 00 00 00 00 00 00 00 00 00 00 00 00 00 00 00 00 00 00 00 00 00 00 00 00 00 00 00 00 00 00 00 00 00 00 00 00 00 00 00 00 00 00 00 00 00 00 00 00 00 00 00 00 00 00 00 00 00 50 41 43 43 30 00 00 00 05 00 00 00 5f 58 46 47 03 00 00 00 01 00 00 00 00 00 00 00 00 00 00 00 00 00 00 00 04 00 00 00 00 00 00 00 00 00 00 00 00 00 00 00 02 00 00 00 00 00 00 00 00 00 00 00 00 00 00 00 00 00 00 00 00 00 00 00 00 00 00 00 00 00 00 00 00 00 00 00 00 00 00 00 00 00 00 00 00 00 00 00 00 00 00 00 00 00 00 00 00 00 00 00 00 00 00 00 00 00 00 00 00 00 00 00 41 47 58 00 00 00 00 00 06 00 00 00 45 4e 4f 4e 03 00 00 00 01 00 00 00 00 00 00 00 00 00 00 00 00 00 00 00 02 00 00 00 04 00 00 00 00 00 00 00 00 00 00 00 02 00 00 00 00 00 00 00 00 00 00 00 00 00 00 00 00 00 00 00 00 00 00 00 00 00 00 00 00 00 00 00 00 00 00 00 00 00 00 00 00 00 00 00 00 00 00 00 00 00 00 00 00 00 00 00 00 00 00 00 00 00 00 00 00 00 00 00 00 00 00 00 41 4e 45 30 00 00 00 00 07 00 00 00 45 4e 4f 4e 01 00 00 00 00 00 00 00 00 00 00 00 00 00 00 00 02 00 00 00 00 00 00 00 00 00 00 00 00 00 00 00 00 00 00 00 01 00 00 00 03 00 00 00 00 00 00 00 00 00 00 00 00 00 00 00 00 00 00 00 00 00 00 00 00 00 00 00 00 00 00 00 00 00 00 00 00 00 00 00 00 00 00 00 00 00 00 00 00 00 00 00 00 00 00 00 00 00 00 00 00 00 00 00 00 00 00 00 49 53 50 00 00 00 00 00 08 00 00 00 45 4e 4f 4e 0b 00 00 00 00 00 00 00 00 00 00 00 00 00 00 00 03 00 00 00 02 00 00 00 00 00 00 00 00 00 00 00 00 00 00 00 02 00 00 00 03 00 00 00 00 00 00 00 00 00 00 00 00 00 00 00 00 00 00 00 00 00 00 00 00 00 00 00 00 00 00 00 00 00 00 00 00 00 00 00 00 00 00 00 00 00 00 00 00 00 00 00 00 00 00 00 00 00 00 00 00 00 00 00 00 00 00 00 44 49 53 50 00 00 00 00 09 00 00 00 45 4e 4f 4e 0b 00 00 00 00 00 00 00 00 00 00 00 00 00 00 00 05 00 00 00 02 00 00 00 00 00 00 00 00 00 00 00 00 00 00 00 02 00 00 00 03 00 00 00 00 00 00 00 00 00 00 00 00 00 00 00 00 00 00 00 00 00 00 00 00 00 00 00 00 00 00 00 00 00 00 00 00 00 00 00 00 00 00 00 00 00 00 00 00 00 00 00 00 00 00 00 00 00 00 00 00 00 00 00 00 00 00 00 44 49 53 50 45 58 54 30 0a 00 00 00 45 4e 4f 4e 0b 00 00 00 00 00 00 00 00 00 00 00 00 00 00 00 05 00 00 00 02 00 00 00 00 00 00 00 00 00 00 00 00 00 00 00 02 00 00 00 03 00 00 00 00 00 00 00 00 00 00 00 00 00 00 00 00 00 00 00 00 00 00 00 00 00 00 00 00 00 00 00 00 00 00 00 00 00 00 00 00 00 00 00 00 00 00 00 00 00 00 00 00 00 00 00 00 00 00 00 00 00 00 00 00 00 00 00 44 49 53 50 45 58 54 31 0b 00 00 00 45 4e 4f 4e 01 00 00 00 00 00 00 00 00 00 00 00 00 00 00 00 02 00 00 00 00 00 00 00 00 00 00 00 00 00 00 00 00 00 00 00 02 00 00 00 00 00 00 00 00 00 00 00 00 00 00 00 00 00 00 00 00 00 00 00 00 00 00 00 00 00 00 00 00 00 00 00 00 00 00 00 00 00 00 00 00 00 00 00 00 00 00 00 00 00 00 00 00 00 00 00 00 00 00 00 00 00 00 00 00 00 00 00 41 56 45 00 00 00 00 00 0c 00 00 00 45 4e 4f 4e 01 00 00 00 00 00 00 00 00 00 00 00 00 00 00 00 02 00 00 00 00 00 00 00 00 00 00 00 00 00 00 00 00 00 00 00 02 00 00 00 00 00 00 00 00 00 00 00 00 00 00 00 00 00 00 00 00 00 00 00 00 00 00 00 00 00 00 00 00 00 00 00 00 00 00 00 00 00 00 00 00 00 00 00 00 00 00 00 00 00 00 00 00 00 00 00 00 00 00 00 00 00 00 00 00 00 00 00 41 56 44 00 00 00 00 00 0d 00 00 00 45 4e 4f 4e 01 00 00 00 00 00 00 00 00 00 00 00 00 00 00 00 02 00 00 00 00 00 00 00 00 00 00 00 00 00 00 00 00 00 00 00 02 00 00 00 00 00 00 00 00 00 00 00 00 00 00 00 00 00 00 00 00 00 00 00 00 00 00 00 00 00 00 00 00 00 00 00 00 00 00 00 00 00 00 00 00 00 00 00 00 00 00 00 00 00 00 00 00 00 00 00 00 00 00 00 00 00 00 00 00 00 00 00 4d 53 52 00 00 00 00 00 0e 00 00 00 45 4e 4f 4e 01 00 00 00 00 00 00 00 00 00 00 00 00 00 00 00 04 00 00 00 00 00 00 00 00 00 00 00 00 00 00 00 00 00 00 00 02 00 00 00 00 00 00 00 00 00 00 00 00 00 00 00 00 00 00 00 00 00 00 00 00 00 00 00 00 00 00 00 00 00 00 00 00 00 00 00 00 00 00 00 00 00 00 00 00 00 00 00 00 00 00 00 00 00 00 00 00 00 00 00 00 00 00 00 00 00 00 00 4a 50 45 47 00 00 00 00 0f 00 00 00 45 4e 4f 4e 01 00 00 00 00 00 00 00 00 00 00 00 00 00 00 00 04 00 00 00 00 00 00 00 00 00 00 00 00 00 00 00 00 00 00 00 02 00 00 00 03 00 00 00 00 00 00 00 00 00 00 00 00 00 00 00 00 00 00 00 00 00 00 00 00 00 00 00 00 00 00 00 00 00 00 00 00 00 00 00 00 00 00 00 00 00 00 00 00 00 00 00 00 00 00 00 00 00 00 00 00 00 00 00 00 00 00 00 53 43 4f 44 45 43 00 00 10 00 00 00 5f 52 54 4c 00 00 00 00 00 00 00 00 00 00 00 00 00 00 00 00 00 00 00 00 00 00 00 00 00 00 00 00 00 00 00 00 00 00 00 00 02 00 00 00 00 00 00 00 00 00 00 00 00 00 00 00 00 00 00 00 00 00 00 00 00 00 00 00 00 00 00 00 00 00 00 00 00 00 00 00 00 00 00 00 00 00 00 00 00 00 00 00 00 00 00 00 00 00 00 00 00 00 00 00 00 00 00 00 00 00 00 00 4c 54 52 00 00 00 00 00 11 00 00 00 45 4e 4f 4e 00 00 00 00 00 00 00 00 00 00 00 00 00 00 00 00 02 00 00 00 00 00 00 00 00 00 00 00 00 00 00 00 00 00 00 00 02 00 00 00 00 00 00 00 00 00 00 00 00 00 00 00 00 00 00 00 00 00 00 00 00 00 00 00 00 00 00 00 00 00 00 00 00 00 00 00 00 00 00 00 00 00 00 00 00 00 00 00 00 00 00 00 00 00 00 00 00 00 00 00 00 00 00 00 00 00 00 00 41 4e 53 00 00 00 00 00 12 00 00 00 45 4e 4f 4e 01 00 00 00 01 00 00 00 00 00 00 00 00 00 00 00 04 00 00 00 00 00 00 00 00 00 00 00 00 00 00 00 00 00 00 00 00 00 00 00 00 00 00 00 00 00 00 00 00 00 00 00 00 00 00 00 00 00 00 00 00 00 00 00 00 00 00 00 00 00 00 00 00 00 00 00 00 00 00 00 00 00 00 00 00 00 00 00 00 00 00 00 00 00 00 00 00 00 00 00 00 00 00 00 00 00 00 00 49 4f 41 30 00 00 00 00 13 00 00 00 45 4e 4f 4e 01 00 00 00 01 00 00 00 00 00 00 00 00 00 00 00 04 00 00 00 00 00 00 00 00 00 00 00 00 00 00 00 00 00 00 00 00 00 00 00 00 00 00 00 00 00 00 00 00 00 00 00 00 00 00 00 00 00 00 00 00 00 00 00 00 00 00 00 00 00 00 00 00 00 00 00 00 00 00 00 00 00 00 00 00 00 00 00 00 00 00 00 00 00 00 00 00 00 00 00 00 00 00 00 00 00 00 00 49 4f 41 31 00 00 00 00 14 00 00 00 45 4e 4f 4e 01 00 00 00 01 00 00 00 00 00 00 00 00 00 00 00 04 00 00 00 00 00 00 00 00 00 00 00 00 00 00 00 00 00 00 00 00 00 00 00 00 00 00 00 00 00 00 00 00 00 00 00 00 00 00 00 00 00 00 00 00 00 00 00 00 00 00 00 00 00 00 00 00 00 00 00 00 00 00 00 00 00 00 00 00 00 00 00 00 00 00 00 00 00 00 00 00 00 00 00 00 00 00 00 00 00 00 00 49 4f 41 32 00 00 00 00 15 00 00 00 45 4e 4f 4e 01 00 00 00 01 00 00 00 00 00 00 00 00 00 00 00 04 00 00 00 00 00 00 00 00 00 00 00 00 00 00 00 00 00 00 00 00 00 00 00 00 00 00 00 00 00 00 00 00 00 00 00 00 00 00 00 00 00 00 00 00 00 00 00 00 00 00 00 00 00 00 00 00 00 00 00 00 00 00 00 00 00 00 00 00 00 00 00 00 00 00 00 00 00 00 00 00 00 00 00 00 00 00 00 00 00 00 00 49 4f 41 33 00 00 00 00];
				apple,tunable-soc-device-ps-group = [f0 7f 00 00 00 00 00 00];
				apple,tunable-soc0-rd-bwr-threshold = [33 33 16 00 99 99 1d 00 66 66 2c 00];
				apple,tunable-soc0-wr-bwr-threshold = [33 33 16 00 99 99 1d 00 66 66 2c 00];
				apple,tunable-soc1-rd-bwr-threshold = [33 33 16 00 99 99 1d 00 66 66 2c 00];
				apple,tunable-soc1-wr-bwr-threshold = [33 33 16 00 99 99 1d 00 66 66 2c 00];
				apple,tunable-sochot-sensors = [01 00 00 00 02 00 00 00 03 00 00 00 04 00 00 00 05 00 00 00 06 00 00 00 07 00 00 00 08 00 00 00 09 00 00 00 0a 00 00 00];
				apple,tunable-sram-index = [01 00 00 00];
				apple,tunable-temp-sensor = [01 00 00 00 06 00 00 00 06 00 00 00 00 00 00 00 00 00 00 00 00 00 00 00 00 00 00 00 00 00 00 00 6e 00 00 00 7d 00 00 00 54 61 30 30 30 6d 00 00 00 00 00 00 00 00 00 00 02 00 00 00 06 00 00 00 03 00 00 00 00 00 00 00 00 00 00 00 00 00 00 00 00 00 00 00 00 00 00 00 6e 00 00 00 7d 00 00 00 54 65 30 30 30 6d 00 00 00 00 00 00 00 00 00 00 03 00 00 00 06 00 00 00 03 00 00 00 01 00 00 00 00 00 00 00 00 00 00 00 00 00 00 00 00 00 00 00 6e 00 00 00 7d 00 00 00 54 65 30 30 31 6d 00 00 00 00 00 00 00 00 00 00 04 00 00 00 06 00 00 00 04 00 00 00 00 00 00 00 00 00 00 00 00 00 00 00 00 00 00 00 00 00 00 00 6e 00 00 00 7d 00 00 00 54 70 30 30 30 6d 00 00 00 00 00 00 00 00 00 00 05 00 00 00 06 00 00 00 04 00 00 00 01 00 00 00 00 00 00 00 00 00 00 00 00 00 00 00 00 00 00 00 6e 00 00 00 7d 00 00 00 54 70 30 30 31 6d 00 00 00 00 00 00 00 00 00 00 06 00 00 00 06 00 00 00 04 00 00 00 02 00 00 00 00 00 00 00 00 00 00 00 00 00 00 00 00 00 00 00 6e 00 00 00 7d 00 00 00 54 70 30 30 32 6d 00 00 00 00 00 00 00 00 00 00 07 00 00 00 04 00 00 00 00 00 00 00 00 00 00 00 00 00 00 00 00 00 00 00 00 00 00 00 00 00 00 00 6e 00 00 00 7d 00 00 00 54 68 30 30 30 69 00 00 00 00 00 00 00 00 00 00 08 00 00 00 04 00 00 00 00 00 00 00 01 00 00 00 00 00 00 00 00 00 00 00 00 00 00 00 00 00 00 00 6e 00 00 00 7d 00 00 00 54 68 30 30 31 69 00 00 00 00 00 00 00 00 00 00 09 00 00 00 04 00 00 00 00 00 00 00 02 00 00 00 00 00 00 00 00 00 00 00 00 00 00 00 00 00 00 00 6e 00 00 00 7d 00 00 00 54 68 30 30 32 69 00 00 00 00 00 00 00 00 00 00 0a 00 00 00 04 00 00 00 00 00 00 00 03 00 00 00 00 00 00 00 00 00 00 00 00 00 00 00 00 00 00 00 6e 00 00 00 7d 00 00 00 54 68 30 30 33 69 00 00 00 00 00 00 00 00 00 00];
				apple,tunable-user-power-managed = [01 00 00 00];
				apple,tunable-uuid = [32 46 34 45 42 34 43 34 2d 30 30 31 42 2d 33 41 43 46 2d 41 39 41 30 2d 36 38 44 38 45 34 32 46 43 33 41 37 00];
			};
		};
	};
};
